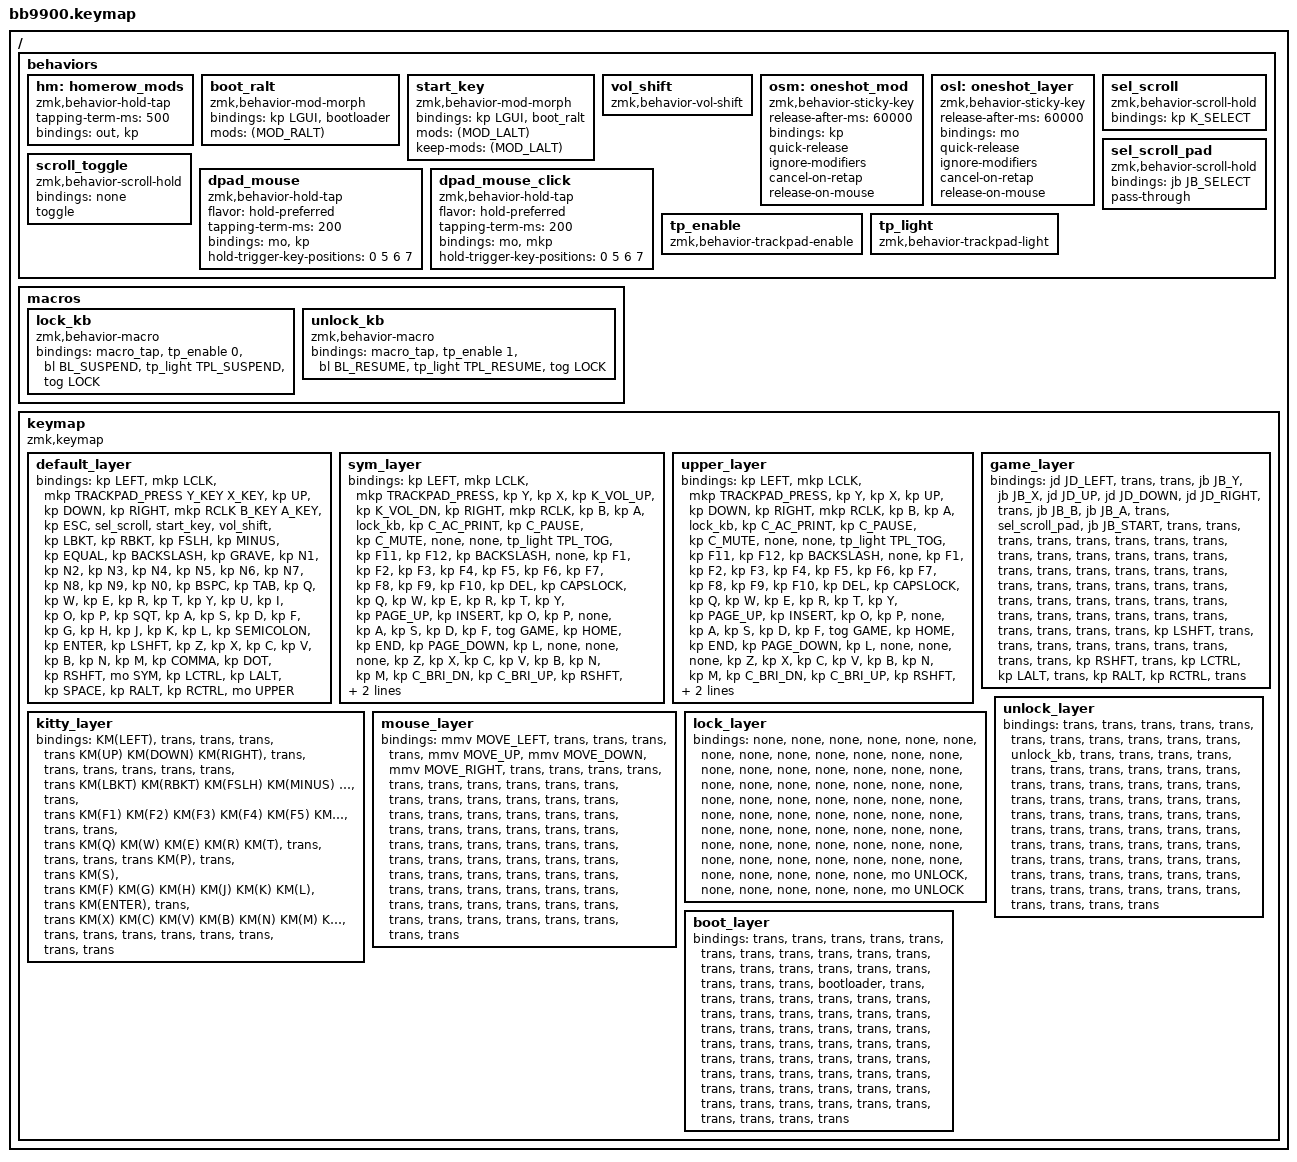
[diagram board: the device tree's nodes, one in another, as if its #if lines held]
/*
 * Copyright (c) 2023 ZitaoTech
 *
 * SPDX-License-Identifier: MIT
 */
   
#include <behaviors.dtsi>
#include <dt-bindings/zmk/keys.h>
#include <dt-bindings/zmk/bt.h>
#include <dt-bindings/zmk/outputs.h>
#include <dt-bindings/zmk/mouse.h>
#include <dt-bindings/zmk/backlight.h>
#include <dt-bindings/zmk/ext_power.h>
#include <dt-bindings/zmk/modifiers.h>
#include <dt-bindings/zmk/joystick.h>
#include <dt-bindings/zmk/trackpad.h>

#define SYM 1
#define UPPER 2
// GAME is gamepad mode, toggled with Fn+G. It sits at index 3 on purpose:
// the layer LED code in the ZMK fork blinks for layer 3.
#define GAME 3
#define KITTY 4
// Held Y or B: the D-pad moves the pointer.
#define MOUSE 5
// Keyboard lock, toggled with Fn+Esc. LOCK swallows every key; UNLOCK is the
// one-key layer the Fn keys reach while locked, holding only the way out.
#define LOCK 6
#define UNLOCK 7
// Second way into the bootloader, a fallback that relies on nothing but
// plain layers: hold Left Fn, then also hold Right Fn, then press the \ key.
#define BOOT 8

// Two mouse buttons that come as a pair: what pressing the trackpad does, and
// what a tap on the B button does. Each is LCLK (left), MCLK (middle) or RCLK
// (right). The standard firmware has left click on the trackpad and middle
// click on B. The middle-click firmware in build.yaml swaps them by defining
// MIDDLE_CLICK_TRACKPAD from the command line. For your own build, change the
// two values after the #else.
#ifdef MIDDLE_CLICK_TRACKPAD
#define TRACKPAD_PRESS MCLK
#define B_CLICK LCLK
#else
#define TRACKPAD_PRESS LCLK
#define B_CLICK MCLK
#endif

// The four face buttons in keyboard mode (default_layer). The one-handed
// firmware in build.yaml defines ONE_HANDED from the command line, which puts
// the mouse buttons and a scroll switch on them for right-hand use, at the
// cost of the D-pad pointer (Y, B) and the kitty key (A). For your own build,
// change the four values after the #else.
#ifdef ONE_HANDED
#define Y_KEY &mkp MCLK
#define X_KEY &scroll_toggle
#define B_KEY &mkp RCLK
#define A_KEY &kp F11
#else
#define Y_KEY &dpad_mouse MOUSE F21
#define X_KEY &kp F22
#define B_KEY &dpad_mouse_click MOUSE B_CLICK
#define A_KEY &osl KITTY
#endif

// Ctrl+Shift+<key>, the kitty_mod chord. Used throughout the KITTY layer.
#define KM(k) &kp LC(LS(k))

// Joystick button numbers in gamepad mode, as on the uConsole QMK firmware.
#define JB_A 0
#define JB_B 1
#define JB_X 2
#define JB_Y 3
#define JB_SELECT 4
#define JB_START 5

 


/ {
    behaviors {
        hm: homerow_mods {
            compatible = "zmk,behavior-hold-tap";
            #binding-cells = <2>;
            tapping-term-ms = <500>;
            bindings = <&out &kp>;
        };
    };

    // Bootloader shortcut: Left Alt + Right Alt + Start, as on the uConsole
    // QMK firmware. The Start key is Super unless both Alt keys are down.
    //
    // A ZMK mod-morph fires when ANY of its listed modifiers is held, not all
    // of them, so one morph listing both Alts would fire on either. Two
    // morphs nested, one modifier each, give a real AND:
    //
    //   start_key: no Left Alt  -> Super
    //              Left Alt     -> boot_ralt, with Left Alt left in place
    //   boot_ralt: no Right Alt -> Super (so Left Alt + Start is Alt+Super)
    //              Right Alt    -> &bootloader
    //
    // Both Alts have to be held: modifiers are plain keys, so tapping an Alt
    // first and then pressing Start just sends Alt+Super. That is why an
    // earlier Ctrl+Alt+\ shortcut was dropped from here, when the modifiers
    // were one-shot and a tapped Ctrl could be left armed by accident.
    //
    // The fallback is in boot_layer: hold Left Fn, then also Right Fn, then
    // press the \ key.
    //
    // This is a mod-morph rather than a ZMK `combos` block because thoughtfix
    // found that any combos block on this board stopped the Enter key working.
    behaviors {
        boot_ralt: boot_ralt {
            compatible = "zmk,behavior-mod-morph";
            #binding-cells = <0>;
            bindings = <&kp LGUI>, <&bootloader>;
            mods = <(MOD_RALT)>;
        };
        start_key: start_key {
            compatible = "zmk,behavior-mod-morph";
            #binding-cells = <0>;
            bindings = <&kp LGUI>, <&boot_ralt>;
            mods = <(MOD_LALT)>;
            keep-mods = <(MOD_LALT)>;
        };
    };

    // Volume/Mute fix (see NOTES.md): Speaker key alone = Volume Down,
    // Shift+Speaker = Volume Up, matching ClusterM's factory-spec
    // do_the_key() behavior. Both Fn layers separately rebound to Mute.
    // A plain mod-morph can't do this correctly on its own: Consumer-page
    // reports have no modifier byte, so Shift stays reported as held the
    // whole time and breaks strict WM keybind matching. vol_shift is a
    // custom behavior (zmk fork, src/behaviors/behavior_vol_shift.c) that
    // explicitly releases and restores the Shift bit around the press.
    behaviors {
        vol_shift: vol_shift {
            compatible = "zmk,behavior-vol-shift";
            #binding-cells = <0>;
        };
    };

    // The one-shot KITTY layer on A, replacing the host-side keyd config
    // (oneshot(kittymod)). Tap = applies to the next key only; hold = a normal
    // momentary layer. keyd has no one-shot timeout; ZMK requires one, so it
    // is set long. Tapping the layer again cancels it (cancel-on-retap), and a
    // mouse click or a trackpad scroll uses it up as a key would
    // (release-on-mouse). Both are additions in the ZMK fork.
    //
    // Shift, Ctrl, Alt and AltGr are plain modifiers, not one-shot: hold one
    // and press a key, as usual. osm below is kept, unused, for anyone who
    // wants them back: bind &osm LSHFT and so on instead of &kp LSHFT.
    behaviors {
        osm: oneshot_mod {
            compatible = "zmk,behavior-sticky-key";
            #binding-cells = <1>;
            release-after-ms = <60000>;
            bindings = <&kp>;
            quick-release;
            ignore-modifiers;
            cancel-on-retap;
            release-on-mouse;
        };
        osl: oneshot_layer {
            compatible = "zmk,behavior-sticky-key";
            #binding-cells = <1>;
            release-after-ms = <60000>;
            bindings = <&mo>;
            quick-release;
            ignore-modifiers;
            cancel-on-retap;
            release-on-mouse;
        };
    };

    // Select: hold and move the trackpad to scroll; a tap with no trackpad
    // movement sends the Select key, as on the uConsole QMK firmware.
    // zmk,behavior-scroll-hold lives in the ZMK fork
    // (src/behaviors/behavior_scroll_hold.c).
    behaviors {
        sel_scroll: sel_scroll {
            compatible = "zmk,behavior-scroll-hold";
            #binding-cells = <0>;
            bindings = <&kp K_SELECT>;
        };
        // Same key in gamepad mode: the joystick Select button, down and up
        // with the key so it responds on press and can be held (pass-through),
        // and still hold-to-scroll.
        sel_scroll_pad: sel_scroll_pad {
            compatible = "zmk,behavior-scroll-hold";
            #binding-cells = <0>;
            bindings = <&jb JB_SELECT>;
            pass-through;
        };
        // A scroll switch: each press turns trackpad scrolling on or off, as
        // on the stock firmware. Only the one-handed firmware uses it, on X.
        // To have one elsewhere, put &scroll_toggle on a key, for example set
        // X_KEY to it. Hold-Select scrolling keeps working alongside it.
        scroll_toggle: scroll_toggle {
            compatible = "zmk,behavior-scroll-hold";
            #binding-cells = <0>;
            bindings = <&none>;
            toggle;
        };
    };

    // Y and B in keyboard mode, as on the uConsole QMK firmware: hold either
    // and the D-pad moves the pointer. A quick tap on its own sends a key
    // (dpad_mouse, on Y) or clicks a mouse button (dpad_mouse_click, on B).
    // Only the D-pad positions (0 5 6 7) turn a press into a hold, so rolling
    // onto any other key keeps it a tap.
    //
    // The click is sent when B is released, and only for a tap shorter than
    // tapping-term-ms, so it cannot be held down to drag. For a button that
    // can, bind the key to plain &mkp instead, which gives up its D-pad hold.
    behaviors {
        dpad_mouse: dpad_mouse {
            compatible = "zmk,behavior-hold-tap";
            #binding-cells = <2>;
            flavor = "hold-preferred";
            tapping-term-ms = <200>;
            bindings = <&mo>, <&kp>;
            hold-trigger-key-positions = <0 5 6 7>;
        };
        dpad_mouse_click: dpad_mouse_click {
            compatible = "zmk,behavior-hold-tap";
            #binding-cells = <2>;
            flavor = "hold-preferred";
            tapping-term-ms = <200>;
            bindings = <&mo>, <&mkp>;
            hold-trigger-key-positions = <0 5 6 7>;
        };
    };

    // Fn+Esc when unlocked (lock_kb): switch the trackpad off, hold the key
    // backlight and the trackpad light off, then lock the keyboard.
    // Fn+Esc again (unlock_kb, bound in unlock_layer): trackpad back on, both
    // lights back to whatever they were, and unlock.
    // Nothing is sent to the host either way. An earlier version also sent
    // the screen lock key, but no desktop binding for it proved reliable on
    // the uConsole, so the lock leaves the screen alone.
    // tp_enable and BL_SUSPEND / BL_RESUME come from the ZMK fork. Neither is
    // saved, and suspend leaves the backlight's own on/off state untouched,
    // which is how the previous state comes back.
    behaviors {
        tp_enable: tp_enable {
            compatible = "zmk,behavior-trackpad-enable";
            #binding-cells = <1>;
        };
    };

    // The trackpad light: Fn + / switches it off or on, and the choice is
    // saved. The lock macros hold it off while locked without touching that
    // choice. zmk,behavior-trackpad-light lives in the ZMK fork.
    behaviors {
        tp_light: tp_light {
            compatible = "zmk,behavior-trackpad-light";
            #binding-cells = <1>;
        };
    };
    macros {
        lock_kb: lock_kb {
            compatible = "zmk,behavior-macro";
            #binding-cells = <0>;
            bindings = <&macro_tap &tp_enable 0 &bl BL_SUSPEND &tp_light TPL_SUSPEND &tog LOCK>;
        };
        unlock_kb: unlock_kb {
            compatible = "zmk,behavior-macro";
            #binding-cells = <0>;
            bindings = <&macro_tap &tp_enable 1 &bl BL_RESUME &tp_light TPL_RESUME &tog LOCK>;
        };
    };

    keymap {
        compatible = "zmk,keymap";

        default_layer {

            bindings = <
//---------------------------------------------------------------------------------------------------------
// |  ←  | ↑   | ↓   | →   |  Mleft  |  Mright |  Trackpad    |  Y  |  B  |  X  |  A  |                                       
// |  ESC   |  SELECT  | Start |                 voive  |   [  |  ]  |   /  |  -  |  =  |  \  |
// |   ~   |  1  |  2  |  3  |  4  |  5  |  6  |  7  |  8  |  9  |  0  |  Backspace  |
// |   TAB   |  Q  |  W  |  E  |  R  |  T  |  Y  |  U  |  I  |  O  |  P  | 
// |    '      |  A  |  S  |  D  |  F  |  G  |  H  |  J  |  K  |  L  |  ;  |     ENTER   |  
// |  LShift  |  Z  |  X  |  C  |  V  |  B  |  N  |  M  |  <  |  >  |  ;  |  RShift  |  
//        |  Fn  |  LCtrl  |  Alt   |      SPACE      |   Alt   |  RCtrl   |  Fn   |  
//        -----------------------------------------------------------------------------------------------------------------
            &kp LEFT                      &mkp LCLK         &mkp TRACKPAD_PRESS  Y_KEY   X_KEY
&kp UP   &kp DOWN &kp RIGHT               &mkp RCLK                       B_KEY  A_KEY
&kp ESC    &sel_scroll  &start_key &vol_shift    &kp LBKT   &kp RBKT   &kp FSLH   &kp MINUS  &kp  EQUAL &kp BACKSLASH
&kp GRAVE  &kp N1        &kp N2     &kp N3   &kp N4     &kp N5     &kp N6     &kp N7     &kp N8    &kp N9  &kp N0 &kp BSPC
&kp TAB     &kp Q         &kp W      &kp E    &kp R      &kp T      &kp Y      &kp U      &kp I     &kp O   &kp P
&kp SQT     &kp A         &kp S      &kp D    &kp F      &kp G      &kp H      &kp J      &kp K     &kp L   &kp SEMICOLON &kp ENTER        
&kp LSHFT   &kp Z         &kp X      &kp C    &kp V      &kp B      &kp N      &kp M      &kp COMMA &kp DOT &kp RSHFT
  &mo SYM   &kp LCTRL               &kp LALT             &kp SPACE           &kp RALT         &kp RCTRL    &mo UPPER        
            >;
        };


        sym_layer {

            bindings = <
        &kp LEFT                      &mkp LCLK         &mkp TRACKPAD_PRESS  &kp Y   &kp X
&kp K_VOL_UP   &kp K_VOL_DN &kp RIGHT               &mkp RCLK                       &kp  B      &kp A
&lock_kb  &kp C_AC_PRINT &kp C_PAUSE  &kp C_MUTE &none   &none   &tp_light TPL_TOG   &kp F11    &kp F12   &kp BACKSLASH
&none    &kp F1         &kp F2        &kp F3     &kp F4     &kp F5     &kp F6     &kp F7     &kp F8    &kp F9  &kp F10 &kp DEL
&kp CAPSLOCK    &kp Q          &kp W         &kp E      &kp R      &kp T      &kp Y      &kp PAGE_UP      &kp INSERT     &kp O   &kp P
&none    &kp A          &kp S         &kp D      &kp F      &tog GAME  &kp HOME      &kp END      &kp PAGE_DOWN     &kp L   &none &none         
&none    &kp Z          &kp X         &kp C      &kp V      &kp B      &kp N      &kp M      &kp C_BRI_DN &kp C_BRI_UP &kp RSHFT
  &none  &kp LCTRL               &kp LGUI             &bl BL_TOG           &kp RALT         &kp RCTRL     &mo BOOT

            >;
        };


        upper_layer {

            bindings = <
        &kp LEFT                      &mkp LCLK         &mkp TRACKPAD_PRESS  &kp Y   &kp X
&kp UP   &kp DOWN &kp RIGHT               &mkp RCLK                       &kp  B      &kp A
&lock_kb  &kp C_AC_PRINT &kp C_PAUSE  &kp C_MUTE &none   &none   &tp_light TPL_TOG   &kp F11    &kp F12   &kp BACKSLASH
&none     &kp F1         &kp F2        &kp F3     &kp F4     &kp F5     &kp F6     &kp F7     &kp F8    &kp F9  &kp F10 &kp DEL
&kp CAPSLOCK    &kp Q          &kp W         &kp E      &kp R      &kp T      &kp Y      &kp PAGE_UP      &kp INSERT     &kp O   &kp P
&none    &kp A          &kp S         &kp D      &kp F      &tog GAME  &kp HOME      &kp END      &kp PAGE_DOWN     &kp L   &none &none         
&none    &kp Z          &kp X         &kp C      &kp V      &kp B      &kp N      &kp M      &kp C_BRI_DN &kp C_BRI_UP &kp RSHFT
  &sys_reset  &kp LCTRL               &kp LALT             &bl BL_TOG           &kp RALT         &kp RCTRL     &none           

            >;
        };


        // Gamepad mode, toggled with Fn+G. The D-pad drives the joystick X/Y
        // axes, A/B/X/Y/Select/Start are joystick buttons 1-6, and modifiers
        // are plain, as everywhere else. Everything else falls through, so the
        // rest of the keyboard, the trackpad and the Fn layers still work.
        // Needs CONFIG_ZMK_JOYSTICK=y (bb9900.conf).
        game_layer {

            bindings = <
            &jd JD_LEFT                   &trans            &trans     &jb JB_Y  &jb JB_X
&jd JD_UP  &jd JD_DOWN  &jd JD_RIGHT      &trans                          &jb JB_B      &jb JB_A
&trans &sel_scroll_pad &jb JB_START &trans &trans &trans &trans &trans &trans &trans
&trans &trans &trans &trans &trans &trans &trans &trans &trans &trans &trans &trans
&trans &trans &trans &trans &trans &trans &trans &trans &trans &trans &trans
&trans &trans &trans &trans &trans &trans &trans &trans &trans &trans &trans &trans
&kp LSHFT &trans &trans &trans &trans &trans &trans &trans &trans &trans &kp RSHFT
  &trans &kp LCTRL &kp LALT &trans &kp RALT &kp RCTRL &trans
            >;
        };


        // One-shot layer on the A button: Ctrl+Shift+<key> for the keys kitty
        // uses, with 1-9 sending Ctrl+Shift+F1..F9. Anything not listed is
        // transparent, so it types normally and ends the one-shot, as in keyd.
        kitty_layer {

            bindings = <
            KM(LEFT)                      &trans            &trans     &trans    &trans
KM(UP)   KM(DOWN) KM(RIGHT)              &trans                          &trans        &trans
&trans     &trans     &trans     &trans     KM(LBKT)   KM(RBKT)   KM(FSLH)   KM(MINUS)  KM(EQUAL)  &trans
&trans     KM(F1)     KM(F2)     KM(F3)     KM(F4)     KM(F5)     KM(F6)     KM(F7)     KM(F8)     KM(F9)     &trans     &trans
&trans     KM(Q)      KM(W)      KM(E)      KM(R)      KM(T)      &trans     &trans     &trans     &trans     KM(P)
&trans     &trans     KM(S)      &trans     KM(F)      KM(G)      KM(H)      KM(J)      KM(K)      KM(L)      &trans     KM(ENTER)
&trans     &trans     KM(X)      KM(C)      KM(V)      KM(B)      KM(N)      KM(M)      KM(COMMA)  KM(DOT)    &trans
  &trans   &trans                &trans                &trans              &trans           &trans        &trans
            >;
        };


        // Active while Y or B is held: the D-pad moves the pointer.
        mouse_layer {

            bindings = <
            &mmv MOVE_LEFT                &trans            &trans     &trans    &trans
&mmv MOVE_UP  &mmv MOVE_DOWN  &mmv MOVE_RIGHT  &trans                     &trans        &trans
&trans &trans &trans &trans &trans &trans &trans &trans &trans &trans
&trans &trans &trans &trans &trans &trans &trans &trans &trans &trans &trans &trans
&trans &trans &trans &trans &trans &trans &trans &trans &trans &trans &trans
&trans &trans &trans &trans &trans &trans &trans &trans &trans &trans &trans &trans
&trans &trans &trans &trans &trans &trans &trans &trans &trans &trans &trans
  &trans &trans &trans &trans &trans &trans &trans
            >;
        };


        // Keyboard lock (Fn+Esc), as on the uConsole QMK firmware: every key
        // and both mouse buttons are ignored until Fn+Esc is pressed again.
        // Locking also switches the trackpad off and turns the key backlight
        // off; unlocking undoes both (see lock_kb / unlock_kb). Being the highest layers, this holds in
        // gamepad mode too. Not saved: a power cycle starts unlocked.
        lock_layer {

            bindings = <
            &none                         &none             &none      &none     &none
&none    &none    &none                   &none                           &none         &none
&none &none &none &none &none &none &none &none &none &none
&none &none &none &none &none &none &none &none &none &none &none &none
&none &none &none &none &none &none &none &none &none &none &none
&none &none &none &none &none &none &none &none &none &none &none &none
&none &none &none &none &none &none &none &none &none &none &none
  &mo UNLOCK &none &none &none &none &none &mo UNLOCK
            >;
        };


        // Reached by holding either Fn while locked. Esc unlocks; everything
        // else falls through to the lock layer and stays ignored.
        unlock_layer {

            bindings = <
            &trans                        &trans            &trans     &trans    &trans
&trans   &trans   &trans                  &trans                          &trans        &trans
&unlock_kb &trans &trans &trans &trans &trans &trans &trans &trans &trans
&trans &trans &trans &trans &trans &trans &trans &trans &trans &trans &trans &trans
&trans &trans &trans &trans &trans &trans &trans &trans &trans &trans &trans
&trans &trans &trans &trans &trans &trans &trans &trans &trans &trans &trans &trans
&trans &trans &trans &trans &trans &trans &trans &trans &trans &trans &trans
  &trans &trans &trans &trans &trans &trans &trans
            >;
        };


        // Left Fn held, then Right Fn as well: this layer sits on top of the
        // left Fn layer and adds one key, \ = bootloader. It is a deliberate
        // three-key, two-handed chord. The Fn keys are plain momentary layers,
        // so unlike a shortcut through a modifier it cannot be armed by
        // earlier taps. Not reachable while the keyboard is locked.
        boot_layer {

            bindings = <
            &trans                        &trans            &trans     &trans    &trans
&trans   &trans   &trans                  &trans                          &trans        &trans
&trans &trans &trans &trans &trans &trans &trans &trans &trans &bootloader
&trans &trans &trans &trans &trans &trans &trans &trans &trans &trans &trans &trans
&trans &trans &trans &trans &trans &trans &trans &trans &trans &trans &trans
&trans &trans &trans &trans &trans &trans &trans &trans &trans &trans &trans &trans
&trans &trans &trans &trans &trans &trans &trans &trans &trans &trans &trans
  &trans &trans &trans &trans &trans &trans &trans
            >;
        };

    };
};

